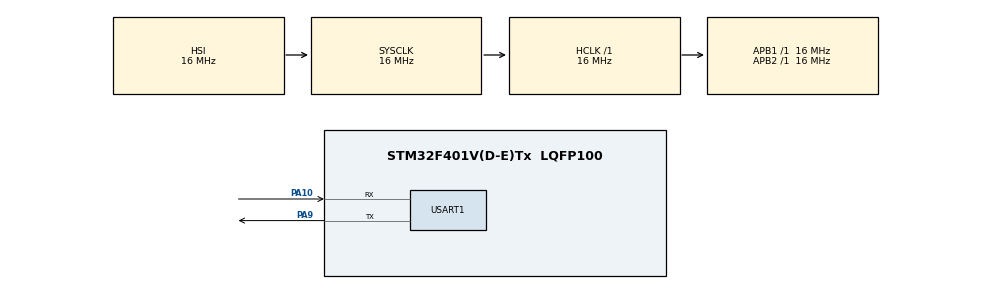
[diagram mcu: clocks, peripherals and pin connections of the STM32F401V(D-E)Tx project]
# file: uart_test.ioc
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Mcu.Family=STM32F4
Mcu.Name=STM32F401V(D-E)Tx
Mcu.Package=LQFP100
NVIC.PriorityGroup=NVIC_PRIORITYGROUP_4
PA10.Mode=Asynchronous
PA10.Signal=USART1_RX
PA9.Mode=Asynchronous
PA9.Signal=USART1_TX
ProjectManager.HeapSize=0x200
ProjectManager.StackSize=0x400
ProjectManager.TargetToolchain=MDK-ARM V5.32
RCC.AHBFreq_Value=16000000
RCC.APB1Freq_Value=16000000
RCC.APB2Freq_Value=16000000
RCC.CortexFreq_Value=16000000
RCC.HSE_VALUE=25000000
RCC.HSI_VALUE=16000000
RCC.LSE_VALUE=32768
RCC.SYSCLKFreq_VALUE=16000000
RCC.VCOOutputFreq_Value=192000000
USART1.VirtualMode=VM_ASYNC
board=custom

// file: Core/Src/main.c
/* USER CODE BEGIN Header */
/**
  ******************************************************************************
  * @file           : main.c
  * @brief          : Main program body
  ******************************************************************************
  * @attention
  *
  * Copyright (c) 2023 STMicroelectronics.
  * All rights reserved.
  *
  * This software is licensed under terms that can be found in the LICENSE file
  * in the root directory of this software component.
  * If no LICENSE file comes with this software, it is provided AS-IS.
  *
  ******************************************************************************
  */
/* USER CODE END Header */
#include "main.h"
#include "usart.h"
#include "gpio.h"

/* USER CODE BEGIN Includes */
#include "stdio.h"
/* USER CODE END Includes */

void SystemClock_Config(void);

/* USER CODE BEGIN 0 */
int fputc(int ch, FILE *f){
	uint8_t temp[1] = {ch};
	// h->hal uart->串口 1 ->1号口
	HAL_UART_Transmit(&huart1, temp, 1, 2);//huart1需要根据你的配置修改(cube生成)
	return ch;
}
/* USER CODE END 0 */

int main(void)
{
	uint8_t message[] = "test";

  /* MCU Configuration--------------------------------------------------------*/

  /* Reset of all peripherals, Initializes the Flash interface and the Systick. */
  HAL_Init();

  /* Configure the system clock */
  SystemClock_Config();

  /* Initialize all configured peripherals */
  MX_GPIO_Init();
  MX_USART1_UART_Init();

  /* Infinite loop */
  /* USER CODE BEGIN WHILE */
  while (1)
  {
		//HAL_UART_Transmit(&huart1,message,5,50);
    /* USER CODE END WHILE */
		printf("[\t main info : stm32 \r \n]");
  }
}

void SystemClock_Config(void)
{
  RCC_OscInitTypeDef RCC_OscInitStruct = {0};
  RCC_ClkInitTypeDef RCC_ClkInitStruct = {0};

  /** Configure the main internal regulator output voltage
  */
  __HAL_RCC_PWR_CLK_ENABLE();
  __HAL_PWR_VOLTAGESCALING_CONFIG(PWR_REGULATOR_VOLTAGE_SCALE2);

  /** Initializes the RCC Oscillators according to the specified parameters
  * in the RCC_OscInitTypeDef structure.
  */
  RCC_OscInitStruct.OscillatorType = RCC_OSCILLATORTYPE_HSI;
  RCC_OscInitStruct.HSIState = RCC_HSI_ON;
  RCC_OscInitStruct.HSICalibrationValue = RCC_HSICALIBRATION_DEFAULT;
  RCC_OscInitStruct.PLL.PLLState = RCC_PLL_NONE;
  if (HAL_RCC_OscConfig(&RCC_OscInitStruct) != HAL_OK)
  {
    Error_Handler();
  }

  /** Initializes the CPU, AHB and APB buses clocks
  */
  RCC_ClkInitStruct.ClockType = RCC_CLOCKTYPE_HCLK|RCC_CLOCKTYPE_SYSCLK
                              |RCC_CLOCKTYPE_PCLK1|RCC_CLOCKTYPE_PCLK2;
  RCC_ClkInitStruct.SYSCLKSource = RCC_SYSCLKSOURCE_HSI;
  RCC_ClkInitStruct.AHBCLKDivider = RCC_SYSCLK_DIV1;
  RCC_ClkInitStruct.APB1CLKDivider = RCC_HCLK_DIV1;
  RCC_ClkInitStruct.APB2CLKDivider = RCC_HCLK_DIV1;

  if (HAL_RCC_ClockConfig(&RCC_ClkInitStruct, FLASH_LATENCY_0) != HAL_OK)
  {
    Error_Handler();
  }
}

void Error_Handler(void)
{
  __disable_irq();
  while (1)
  {
  }
}
